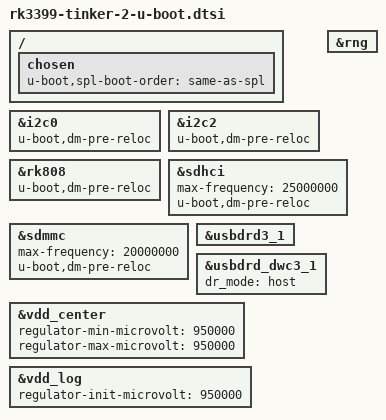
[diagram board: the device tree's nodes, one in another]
// SPDX-License-Identifier: GPL-2.0+
/*
 * Copyright (C) 2021 Thomas McKahan <tmckahan@singleboardsolutions.com>
 */

#include "rk3399-u-boot.dtsi"
#include "rk3399-sdram-lpddr4-100.dtsi"

/ {
	chosen {
		u-boot,spl-boot-order = "same-as-spl", &sdhci, &sdmmc ;
	};
};



&i2c0 {
	u-boot,dm-pre-reloc;
};

&i2c2 {
	u-boot,dm-pre-reloc;
	
};

&rk808 {
	u-boot,dm-pre-reloc;
};

&rng {
	status = "okay";
};

&sdhci {
	max-frequency = <25000000>;
	u-boot,dm-pre-reloc;
};

&sdmmc {
	max-frequency = <20000000>;
	u-boot,dm-pre-reloc;
};

&usbdrd3_1 {
	status = "okay";
};

&usbdrd_dwc3_1 {
	dr_mode = "host";
	status = "okay";
};

&vdd_center {
	regulator-min-microvolt = <950000>;
	regulator-max-microvolt = <950000>;
};

&vdd_log {
	regulator-init-microvolt = <950000>;
};
